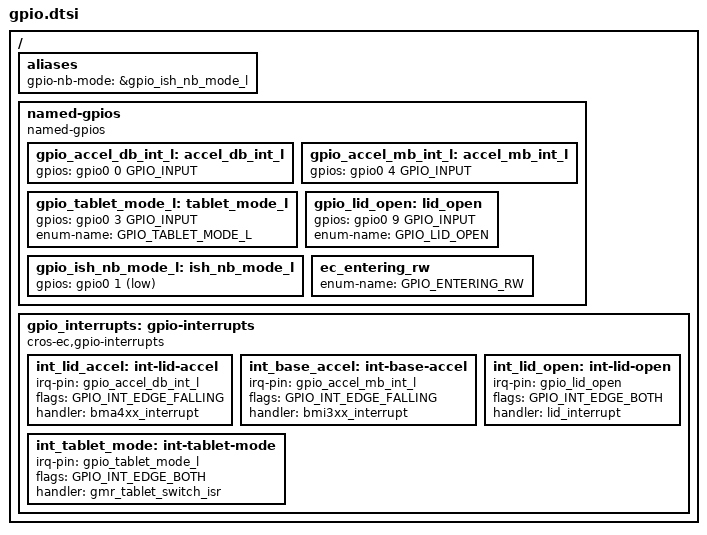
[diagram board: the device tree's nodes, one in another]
/* Copyright 2026 The ChromiumOS Authors
 * Use of this source code is governed by a BSD-style license that can be
 * found in the LICENSE file.
 */
#include <dt-bindings/gpio_defines.h>

/ {

	aliases {
		gpio-nb-mode = &gpio_ish_nb_mode_l;
	};

	named-gpios {
		compatible = "named-gpios";

		gpio_accel_db_int_l: accel_db_int_l {
			gpios = <&gpio0 0 GPIO_INPUT>;
		};

		gpio_accel_mb_int_l: accel_mb_int_l {
			gpios = <&gpio0 4 GPIO_INPUT>;
		};

		gpio_tablet_mode_l: tablet_mode_l {
			gpios = <&gpio0 3 GPIO_INPUT>;
			enum-name = "GPIO_TABLET_MODE_L";
		};

		gpio_lid_open: lid_open {
			gpios = <&gpio0 9 GPIO_INPUT>;
			enum-name = "GPIO_LID_OPEN";
		};

		gpio_ish_nb_mode_l: ish_nb_mode_l {
			gpios = <&gpio0 1 (GPIO_ACTIVE_LOW | GPIO_OUTPUT_ACTIVE)>;
		};

		ec_entering_rw {
			enum-name = "GPIO_ENTERING_RW";
		};
	};

	gpio_interrupts: gpio-interrupts {
		compatible = "cros-ec,gpio-interrupts";

		int_lid_accel: int-lid-accel {
			irq-pin = <&gpio_accel_db_int_l>;
			flags = <GPIO_INT_EDGE_FALLING>;
			handler = "bma4xx_interrupt";
		};

		int_base_accel: int-base-accel {
			irq-pin = <&gpio_accel_mb_int_l>;
			flags = <GPIO_INT_EDGE_FALLING>;
			handler = "bmi3xx_interrupt";
		};

		int_lid_open: int-lid-open {
			irq-pin = <&gpio_lid_open>;
			flags = <GPIO_INT_EDGE_BOTH>;
			handler = "lid_interrupt";
		};

		int_tablet_mode: int-tablet-mode {
			irq-pin = <&gpio_tablet_mode_l>;
			flags = <GPIO_INT_EDGE_BOTH>;
			handler = "gmr_tablet_switch_isr";
		};
	};
};
